# FAULTMUX register map
Vendor: Texas Instruments
Registers are 32-bit, access per field, no defined reset value unless marked. A register's access mark holds for its fields unless they carry their own. Offsets are as the file gives them; [hi:lo] are bit positions; {n}, {i} and the like mark numbered series; 'fields as' and 'values as' point back to an identical list.

## FAULTMUX (part 2 of 2) — top level module
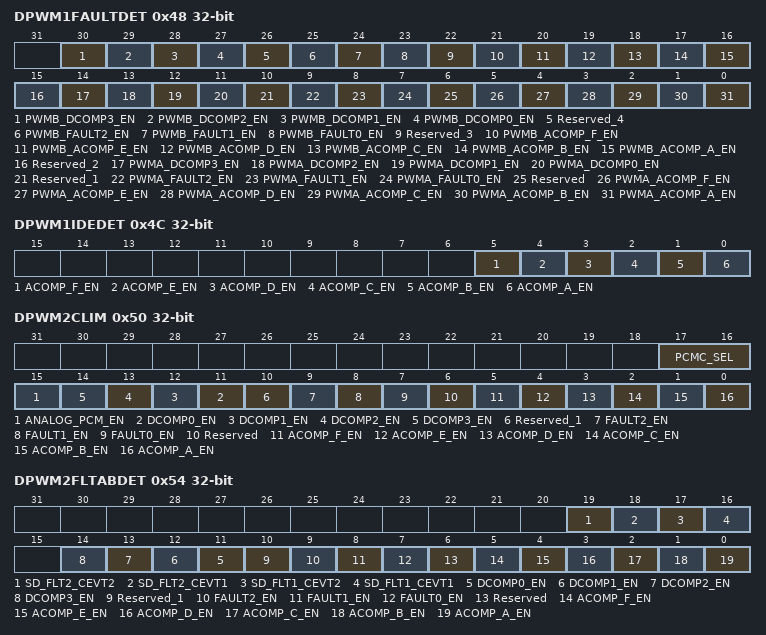
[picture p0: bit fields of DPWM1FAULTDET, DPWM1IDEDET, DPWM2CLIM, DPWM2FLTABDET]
0x48 DPWM1FAULTDET — DPWM 1 Fault Detection Register
  [30] PWMB_DCOMP3_EN rw — Enables Digital Comparator 3 result for DPWM_1 PWM-B Fault Detection
    1=enable (Digital Comparator 3 enabled for fault detection); 0=disbaled (Digital Comparator 3 disabled for fault detection (Default))
  [29] PWMB_DCOMP2_EN rw — Enables Digital Comparator 2 result for DPWM_1 PWM-B Fault Detection
    1=enable (Digital Comparator 2 enabled for fault detection); 0=disbaled (Digital Comparator 2 disabled for fault detection (Default))
  [28] PWMB_DCOMP1_EN rw — Enables Digital Comparator 1 result for DPWM_1 PWM-B Fault Detection
    1=enable (Digital Comparator 1 enabled for fault detection); 0=disbaled (Digital Comparator 1 disabled for fault detection (Default))
  [27] PWMB_DCOMP0_EN rw — Enables Digital Comparator 3 result for DPWM_1 PWM-B Fault Detection
    values as PWMB_DCOMP3_EN
  [26] Reserved_4 ro — Enables FAULT[3] pin for DPWM_1 PWM-B Fault Detection
    1=enable (External Fault pin enabled for fault detection); 0=disbaled (External Fault pin disabled for fault detection (Default))
  [25] PWMB_FAULT2_EN rw — Enables FAULT[2] pin for DPWM_1 PWM-B Fault Detection
    values as Reserved_4
  [24] PWMB_FAULT1_EN rw — Enables FAULT[1] pin for DPWM_1 PWM-B Fault Detection
    values as Reserved_4
  [23] PWMB_FAULT0_EN rw — Enables FAULT[0] pin for DPWM_1 PWM-B Fault Detection
    values as Reserved_4
  [22] Reserved_3 ro — Enables Analog Comparator G result for DPWM_1 PWM-B Fault detection
    1=enable (Analog Comparator result enabled for fault detection); 0=disbaled (Analog Comparator result disabled for fault detection (Default))
  [21] PWMB_ACOMP_F_EN rw — Enables Analog Comparator F result for DPWM_1 PWM-B Fault detection
    values as Reserved_3
  [20] PWMB_ACOMP_E_EN rw — Enables Analog Comparator E result for DPWM_1 PWM-B Fault detection
    values as Reserved_3
  [19] PWMB_ACOMP_D_EN rw — Enables Analog Comparator D result for DPWM_1 PWM-B Fault detection
    values as Reserved_3
  [18] PWMB_ACOMP_C_EN rw — Enables Analog Comparator C result for DPWM_1 PWM-B Fault detection
    values as Reserved_3
  [17] PWMB_ACOMP_B_EN rw — Enables Analog Comparator B result for DPWM_1 PWM-B Fault detection
    values as Reserved_3
  [16] PWMB_ACOMP_A_EN rw — Enables Analog Comparator A result for DPWM_1 PWM-B Fault detection
    values as Reserved_3
  [15] Reserved_2 ro — RESEVED
  [14] PWMA_DCOMP3_EN rw — Enables Digital Comparator 3 result for DPWM_1 PWM-A Fault Detection
    values as PWMB_DCOMP3_EN
  [13] PWMA_DCOMP2_EN rw — Enables Digital Comparator 2 result for DPWM_1 PWM-A Fault Detection
    values as PWMB_DCOMP2_EN
  [12] PWMA_DCOMP1_EN rw — Enables Digital Comparator 1 result for DPWM_1 PWM-A Fault Detection
    values as PWMB_DCOMP1_EN
  [11] PWMA_DCOMP0_EN rw — Enables Digital Comparator 3 result for DPWM_1 PWM-A Fault Detection
    values as PWMB_DCOMP3_EN
  [10] Reserved_1 ro — Enables FAULT[3] pin for DPWM_1 PWM-A Fault Detection
    values as Reserved_4
  [9] PWMA_FAULT2_EN rw — Enables FAULT[2] pin for DPWM_1 PWM-A Fault Detection
    values as Reserved_4
  [8] PWMA_FAULT1_EN rw — Enables FAULT[1] pin for DPWM_1 PWM-A Fault Detection
    values as Reserved_4
  [7] PWMA_FAULT0_EN rw — Enables FAULT[0] pin for DPWM_1 PWM-A Fault Detection
    values as Reserved_4
  [6] Reserved ro — Enables Analog Comparator G result for DPWM_1 PWM-A Fault detection
    values as Reserved_3
  [5] PWMA_ACOMP_F_EN rw — Enables Analog Comparator F result for DPWM_1 PWM-A Fault detection
    values as Reserved_3
  [4] PWMA_ACOMP_E_EN rw — Enables Analog Comparator E result for DPWM_1 PWM-A Fault detection
    values as Reserved_3
  [3] PWMA_ACOMP_D_EN rw — Enables Analog Comparator D result for DPWM_1 PWM-A Fault detection
    values as Reserved_3
  [2] PWMA_ACOMP_C_EN rw — Enables Analog Comparator C result for DPWM_1 PWM-A Fault detection
    values as Reserved_3
  [1] PWMA_ACOMP_B_EN rw — Enables Analog Comparator B result for DPWM_1 PWM-A Fault detection
    values as Reserved_3
  [0] PWMA_ACOMP_A_EN rw — Enables Analog Comparator A result for DPWM_1 PWM-A Fault detection
    values as Reserved_3
0x4C DPWM1IDEDET rw — DPWM 1 IDE detection register
  [all] fields
    1=enable; 0=disable
  [5] ACOMP_F_EN — Enables Analog Comparator F result for DPWM1 IDE detection
  [4] ACOMP_E_EN — Enables Analog Comparator E result for DPWM1 IDE detection
  [3] ACOMP_D_EN — Enables Analog Comparator D result for DPWM1 IDE detection
  [2] ACOMP_C_EN — Enables Analog Comparator C result for DPWM1 IDE detection
  [1] ACOMP_B_EN — Enables Analog Comparator B result for DPWM1 IDE detection
  [0] ACOMP_A_EN — Enables Analog Comparator A result for DPWM1 IDE detection
0x50 DPWM2CLIM access not given — DPWM_2 Current Limit Control Register
  [17:16] PCMC_SEL — Selects the PCMC module to trigger PCMC- CBC fault
    2=PCMC3; 1=PCMC2; 0=PCMC1
  [15] ANALOG_PCM_EN rw — Enables Analog Peak Current detection result for DPWM_2 Current Limit
    1=enabled (Analog Peak Current detection enabled for current limit); 0=disabled (Analog Peak Current detection disabled for current limit (Default))
  [n+11] DCOMP{n}_EN rw (n=0..3) — Enables Digital Comparator {n} result for DPWM_2 Current Limit
    values as ANALOG_PCM_EN
  [10] Reserved_1 ro — Enables FAULT[3] pin for DPWM_2 Current Limit
    1=enabled (External Fault pin enabled for current limit); 0=disabled (External Fault pin disabled for current limit (Default))
  [9] FAULT2_EN rw — Enables FAULT[2] pin for DPWM_2 Current Limit
    values as Reserved_1
  [8] FAULT1_EN rw — Enables FAULT[1] pin for DPWM_2 Current Limit
    values as Reserved_1
  [7] FAULT0_EN rw — Enables FAULT[0] pin for DPWM_2 Current Limit
    values as Reserved_1
  [6] Reserved ro — Enables Analog Comparator G result for DPWM_2 Current Limit
    1=enabled (Analog Comparator result enabled for current limit); 0=disabled (Analog Comparator result disabled for current limit (Default))
  [5] ACOMP_F_EN rw — Enables Analog Comparator F result for DPWM_2 Current Limit
    values as Reserved
  [4] ACOMP_E_EN rw — Enables Analog Comparator E result for DPWM_2 Current Limit
    values as Reserved
  [3] ACOMP_D_EN rw — Enables Analog Comparator D result for DPWM_2 Current Limit
    values as Reserved
  [2] ACOMP_C_EN rw — Enables Analog Comparator C result for DPWM_2 Current Limit
    values as Reserved
  [1] ACOMP_B_EN rw — Enables Analog Comparator B result for DPWM_2 Current Limit
    values as Reserved
  [0] ACOMP_A_EN rw — Enables Analog Comparator A result for DPWM_2 Current Limit
    values as Reserved
0x54 DPWM2FLTABDET — DPWM_2 Fault AB Detection Register
  [19] SD_FLT2_CEVT2 rw — Enables SDFM Filter2 Compare Event 2 output for DPWM2 Fault detection
  [18] SD_FLT2_CEVT1 rw — Enables SDFM Filter2 Compare Event 1 output for DPWM2 Fault detection
  [17] SD_FLT1_CEVT2 rw — Enables SDFM Filter1 Compare Event 2 output for DPWM2 Fault detection
  [16] SD_FLT1_CEVT1 rw — Enables SDFM Filter1 Compare Event 1 output for DPWM2 Fault detection
  [n+11] DCOMP{n}_EN rw (n=0..3) — Enables Digital Comparator {n} result for DPWM_2 Fault AB Detection
    1=enable (Digital Comparator {n} result enabled for current limit); 0=disable (Digital Comparator {n} result disabled for current limit (Default))
  [10] Reserved_1 ro — Enables FAULT[3] pin for DPWM_2 Current Limit
    1=enable (External Fault pin enabled for current limit); 0=disable (External Fault pin disabled for current limit (Default))
  [9] FAULT2_EN rw — Enables FAULT[2] pin for DPWM_2 Fault AB Detection
    values as Reserved_1
  [8] FAULT1_EN rw — Enables FAULT[1] pin for DPWM_2 Fault AB Detection
    values as Reserved_1
  [7] FAULT0_EN rw — Enables FAULT[0] pin for DPWM_2 Fault AB Detection
    values as Reserved_1
  [6] Reserved ro — Enables Analog Comparator G result for DPWM_2 Current Limit
    1=enable (Analog Comparator result enabled for current limit); 0=disable (Analog Comparator result disabled for current limit (Default))
  [5] ACOMP_F_EN rw — Enables Analog Comparator F result for DPWM_2 Fault AB Detection
    values as Reserved
  [4] ACOMP_E_EN rw — Enables Analog Comparator E result for DPWM_2 Fault AB Detection
    values as Reserved
  [3] ACOMP_D_EN rw — Enables Analog Comparator D result for DPWM_2 Fault AB Detection
    values as Reserved
  [2] ACOMP_C_EN rw — Enables Analog Comparator C result for DPWM_2 Fault AB Detection
    values as Reserved
  [1] ACOMP_B_EN rw — Enables Analog Comparator B result for DPWM_2 Fault AB Detection
    values as Reserved
  [0] ACOMP_A_EN rw — Enables Analog Comparator A result for DPWM_2 Fault AB Detection
    values as Reserved
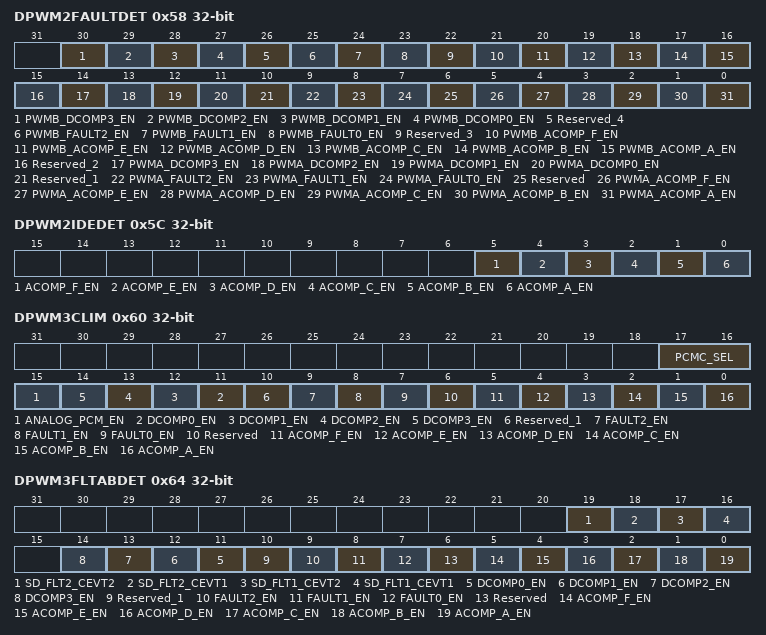
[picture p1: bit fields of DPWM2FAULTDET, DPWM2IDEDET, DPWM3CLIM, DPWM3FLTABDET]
0x58 DPWM2FAULTDET — DPWM_2 Fault Detection Register
  [30] PWMB_DCOMP3_EN rw — Enables Digital Comparator 3 result for DPWM_2 PWM-B Fault Detection
    values as DPWM1FAULTDET.PWMB_DCOMP3_EN
  [29] PWMB_DCOMP2_EN rw — Enables Digital Comparator 2 result for DPWM_2 PWM-B Fault Detection
    values as DPWM1FAULTDET.PWMB_DCOMP2_EN
  [28] PWMB_DCOMP1_EN rw — Enables Digital Comparator 1 result for DPWM_2 PWM-B Fault Detection
    values as DPWM1FAULTDET.PWMB_DCOMP1_EN
  [27] PWMB_DCOMP0_EN rw — Enables Digital Comparator 3 result for DPWM_2 PWM-B Fault Detection
    values as DPWM1FAULTDET.PWMB_DCOMP3_EN
  [26] Reserved_4 ro — Enables FAULT[3] pin for DPWM_2 PWM-B Fault Detection
    values as DPWM1FAULTDET.Reserved_4
  [25] PWMB_FAULT2_EN rw — Enables FAULT[2] pin for DPWM_2 PWM-B Fault Detection
    values as DPWM1FAULTDET.Reserved_4
  [24] PWMB_FAULT1_EN rw — Enables FAULT[1] pin for DPWM_2 PWM-B Fault Detection
    values as DPWM1FAULTDET.Reserved_4
  [23] PWMB_FAULT0_EN rw — Enables FAULT[0] pin for DPWM_2 PWM-B Fault Detection
    values as DPWM1FAULTDET.Reserved_4
  [22] Reserved_3 ro — Enables Analog Comparator G result for DPWM_2 PWM-B Fault detection
    values as DPWM1FAULTDET.Reserved_3
  [21] PWMB_ACOMP_F_EN rw — Enables Analog Comparator F result for DPWM_2 PWM-B Fault detection
    values as DPWM1FAULTDET.Reserved_3
  [20] PWMB_ACOMP_E_EN rw — Enables Analog Comparator E result for DPWM_2 PWM-B Fault detection
    values as DPWM1FAULTDET.Reserved_3
  [19] PWMB_ACOMP_D_EN rw — Enables Analog Comparator D result for DPWM_2 PWM-B Fault detection
    values as DPWM1FAULTDET.Reserved_3
  [18] PWMB_ACOMP_C_EN rw — Enables Analog Comparator C result for DPWM_2 PWM-B Fault detection
    values as DPWM1FAULTDET.Reserved_3
  [17] PWMB_ACOMP_B_EN rw — Enables Analog Comparator B result for DPWM_2 PWM-B Fault detection
    values as DPWM1FAULTDET.Reserved_3
  [16] PWMB_ACOMP_A_EN rw — Enables Analog Comparator A result for DPWM_2 PWM-B Fault detection
    values as DPWM1FAULTDET.Reserved_3
  [15] Reserved_2 ro — RESEVED
  [14] PWMA_DCOMP3_EN rw — Enables Digital Comparator 3 result for DPWM_2 PWM-A Fault Detection
    values as DPWM1FAULTDET.PWMB_DCOMP3_EN
  [13] PWMA_DCOMP2_EN rw — Enables Digital Comparator 2 result for DPWM_2 PWM-A Fault Detection
    values as DPWM1FAULTDET.PWMB_DCOMP2_EN
  [12] PWMA_DCOMP1_EN rw — Enables Digital Comparator 1 result for DPWM_2 PWM-A Fault Detection
    values as DPWM1FAULTDET.PWMB_DCOMP1_EN
  [11] PWMA_DCOMP0_EN rw — Enables Digital Comparator 3 result for DPWM_2 PWM-A Fault Detection
    values as DPWM1FAULTDET.PWMB_DCOMP3_EN
  [10] Reserved_1 ro — Enables FAULT[3] pin for DPWM_2 PWM-A Fault Detection
    values as DPWM1FAULTDET.Reserved_4
  [9] PWMA_FAULT2_EN rw — Enables FAULT[2] pin for DPWM_2 PWM-A Fault Detection
    values as DPWM1FAULTDET.Reserved_4
  [8] PWMA_FAULT1_EN rw — Enables FAULT[1] pin for DPWM_2 PWM-A Fault Detection
    values as DPWM1FAULTDET.Reserved_4
  [7] PWMA_FAULT0_EN rw — Enables FAULT[0] pin for DPWM_2 PWM-A Fault Detection
    values as DPWM1FAULTDET.Reserved_4
  [6] Reserved ro — Enables Analog Comparator G result for DPWM_2 PWM-A Fault detection
    values as DPWM1FAULTDET.Reserved_3
  [5] PWMA_ACOMP_F_EN rw — Enables Analog Comparator F result for DPWM_2 PWM-A Fault detection
    values as DPWM1FAULTDET.Reserved_3
  [4] PWMA_ACOMP_E_EN rw — Enables Analog Comparator E result for DPWM_2 PWM-A Fault detection
    values as DPWM1FAULTDET.Reserved_3
  [3] PWMA_ACOMP_D_EN rw — Enables Analog Comparator D result for DPWM_2 PWM-A Fault detection
    values as DPWM1FAULTDET.Reserved_3
  [2] PWMA_ACOMP_C_EN rw — Enables Analog Comparator C result for DPWM_2 PWM-A Fault detection
    values as DPWM1FAULTDET.Reserved_3
  [1] PWMA_ACOMP_B_EN rw — Enables Analog Comparator B result for DPWM_2 PWM-A Fault detection
    values as DPWM1FAULTDET.Reserved_3
  [0] PWMA_ACOMP_A_EN rw — Enables Analog Comparator A result for DPWM_2 PWM-A Fault detection
    values as DPWM1FAULTDET.Reserved_3
0x5C DPWM2IDEDET rw — DPWM 2 IDE detection register
  [all] fields
    1=enable; 0=disable
  [5] ACOMP_F_EN — Enables Analog Comparator F result for DPWM2 IDE detection
  [4] ACOMP_E_EN — Enables Analog Comparator E result for DPWM2 IDE detection
  [3] ACOMP_D_EN — Enables Analog Comparator D result for DPWM2 IDE detection
  [2] ACOMP_C_EN — Enables Analog Comparator C result for DPWM2 IDE detection
  [1] ACOMP_B_EN — Enables Analog Comparator B result for DPWM2 IDE detection
  [0] ACOMP_A_EN — Enables Analog Comparator A result for DPWM2 IDE detection
0x60 DPWM3CLIM access not given — DPWM_3 Current Limit Control Register
  [17:16] PCMC_SEL — Selects the PCMC module to trigger PCMC- CBC fault
    2=PCMC3; 1=PCMC2; 0=PCMC1
  [15] ANALOG_PCM_EN rw — Enables Analog Peak Current detection result for DPWM_3 Current Limit
    values as DPWM2CLIM.ANALOG_PCM_EN
  [n+11] DCOMP{n}_EN rw (n=0..3) — Enables Digital Comparator {n} result for DPWM_3 Current Limit
    values as DPWM2CLIM.ANALOG_PCM_EN
  [10] Reserved_1 ro — Enables FAULT[3] pin for DPWM_3 Current Limit
    values as DPWM2CLIM.Reserved_1
  [9] FAULT2_EN rw — Enables FAULT[2] pin for DPWM_3 Current Limit
    values as DPWM2CLIM.Reserved_1
  [8] FAULT1_EN rw — Enables FAULT[1] pin for DPWM_3 Current Limit
    values as DPWM2CLIM.Reserved_1
  [7] FAULT0_EN rw — Enables FAULT[0] pin for DPWM_3 Current Limit
    values as DPWM2CLIM.Reserved_1
  [6] Reserved ro — Enables Analog Comparator G result for DPWM_3 Current Limit
    values as DPWM2CLIM.Reserved
  [5] ACOMP_F_EN rw — Enables Analog Comparator F result for DPWM_3 Current Limit
    values as DPWM2CLIM.Reserved
  [4] ACOMP_E_EN rw — Enables Analog Comparator E result for DPWM_3 Current Limit
    values as DPWM2CLIM.Reserved
  [3] ACOMP_D_EN rw — Enables Analog Comparator D result for DPWM_3 Current Limit
    values as DPWM2CLIM.Reserved
  [2] ACOMP_C_EN rw — Enables Analog Comparator C result for DPWM_3 Current Limit
    values as DPWM2CLIM.Reserved
  [1] ACOMP_B_EN rw — Enables Analog Comparator B result for DPWM_3 Current Limit
    values as DPWM2CLIM.Reserved
  [0] ACOMP_A_EN rw — Enables Analog Comparator A result for DPWM_3 Current Limit
    values as DPWM2CLIM.Reserved
0x64 DPWM3FLTABDET — DPWM_3 Fault AB Detection Register
  [19] SD_FLT2_CEVT2 rw — Enables SDFM Filter2 Compare Event 2 output for DPWM3 Fault detection
  [18] SD_FLT2_CEVT1 rw — Enables SDFM Filter2 Compare Event 1 output for DPWM3 Fault detection
  [17] SD_FLT1_CEVT2 rw — Enables SDFM Filter1 Compare Event 2 output for DPWM3 Fault detection
  [16] SD_FLT1_CEVT1 rw — Enables SDFM Filter1 Compare Event 1 output for DPWM3 Fault detection
  [n+11] DCOMP{n}_EN rw (n=0..3) — Enables Digital Comparator {n} result for DPWM_3 Fault AB Detection
    values as DPWM2FLTABDET.DCOMP0_EN
  [10] Reserved_1 ro — Enables FAULT[3] pin for DPWM_3 Current Limit
    values as DPWM2FLTABDET.Reserved_1
  [9] FAULT2_EN rw — Enables FAULT[2] pin for DPWM_3 Fault AB Detection
    values as DPWM2FLTABDET.Reserved_1
  [8] FAULT1_EN rw — Enables FAULT[1] pin for DPWM_3 Fault AB Detection
    values as DPWM2FLTABDET.Reserved_1
  [7] FAULT0_EN rw — Enables FAULT[0] pin for DPWM_3 Fault AB Detection
    values as DPWM2FLTABDET.Reserved_1
  [6] Reserved ro — Enables Analog Comparator G result for DPWM_3 Current Limit
    values as DPWM2FLTABDET.Reserved
  [5] ACOMP_F_EN rw — Enables Analog Comparator F result for DPWM_3 Fault AB Detection
    values as DPWM2FLTABDET.Reserved
  [4] ACOMP_E_EN rw — Enables Analog Comparator E result for DPWM_3 Fault AB Detection
    values as DPWM2FLTABDET.Reserved
  [3] ACOMP_D_EN rw — Enables Analog Comparator D result for DPWM_3 Fault AB Detection
    values as DPWM2FLTABDET.Reserved
  [2] ACOMP_C_EN rw — Enables Analog Comparator C result for DPWM_3 Fault AB Detection
    values as DPWM2FLTABDET.Reserved
  [1] ACOMP_B_EN rw — Enables Analog Comparator B result for DPWM_3 Fault AB Detection
    values as DPWM2FLTABDET.Reserved
  [0] ACOMP_A_EN rw — Enables Analog Comparator A result for DPWM_3 Fault AB Detection
    values as DPWM2FLTABDET.Reserved
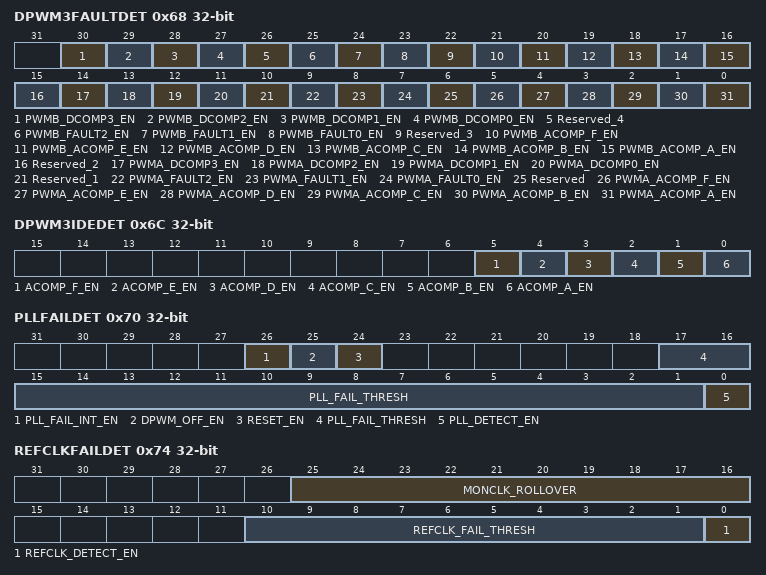
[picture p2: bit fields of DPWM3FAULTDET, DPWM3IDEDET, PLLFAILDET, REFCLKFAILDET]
0x68 DPWM3FAULTDET — DPWM 1 Fault Detection Register
  [30] PWMB_DCOMP3_EN rw — Enables Digital Comparator 3 result for DPWM_3 PWM-B Fault Detection
    values as DPWM1FAULTDET.PWMB_DCOMP3_EN
  [29] PWMB_DCOMP2_EN rw — Enables Digital Comparator 2 result for DPWM_3 PWM-B Fault Detection
    values as DPWM1FAULTDET.PWMB_DCOMP2_EN
  [28] PWMB_DCOMP1_EN rw — Enables Digital Comparator 1 result for DPWM_3 PWM-B Fault Detection
    values as DPWM1FAULTDET.PWMB_DCOMP1_EN
  [27] PWMB_DCOMP0_EN rw — Enables Digital Comparator 3 result for DPWM_3 PWM-B Fault Detection
    values as DPWM1FAULTDET.PWMB_DCOMP3_EN
  [26] Reserved_4 ro — Enables FAULT[3] pin for DPWM_3 PWM-B Fault Detection
    values as DPWM1FAULTDET.Reserved_4
  [25] PWMB_FAULT2_EN rw — Enables FAULT[2] pin for DPWM_3 PWM-B Fault Detection
    values as DPWM1FAULTDET.Reserved_4
  [24] PWMB_FAULT1_EN rw — Enables FAULT[1] pin for DPWM_3 PWM-B Fault Detection
    values as DPWM1FAULTDET.Reserved_4
  [23] PWMB_FAULT0_EN rw — Enables FAULT[0] pin for DPWM_3 PWM-B Fault Detection
    values as DPWM1FAULTDET.Reserved_4
  [22] Reserved_3 ro — Enables Analog Comparator G result for DPWM_3 PWM-B Fault detection
    values as DPWM1FAULTDET.Reserved_3
  [21] PWMB_ACOMP_F_EN rw — Enables Analog Comparator F result for DPWM_3 PWM-B Fault detection
    values as DPWM1FAULTDET.Reserved_3
  [20] PWMB_ACOMP_E_EN rw — Enables Analog Comparator E result for DPWM_3 PWM-B Fault detection
    values as DPWM1FAULTDET.Reserved_3
  [19] PWMB_ACOMP_D_EN rw — Enables Analog Comparator D result for DPWM_3 PWM-B Fault detection
    values as DPWM1FAULTDET.Reserved_3
  [18] PWMB_ACOMP_C_EN rw — Enables Analog Comparator C result for DPWM_3 PWM-B Fault detection
    values as DPWM1FAULTDET.Reserved_3
  [17] PWMB_ACOMP_B_EN rw — Enables Analog Comparator B result for DPWM_3 PWM-B Fault detection
    values as DPWM1FAULTDET.Reserved_3
  [16] PWMB_ACOMP_A_EN rw — Enables Analog Comparator A result for DPWM_3 PWM-B Fault detection
    values as DPWM1FAULTDET.Reserved_3
  [15] Reserved_2 ro — RESEVED
  [14] PWMA_DCOMP3_EN rw — Enables Digital Comparator 3 result for DPWM_3 PWM-A Fault Detection
    values as DPWM1FAULTDET.PWMB_DCOMP3_EN
  [13] PWMA_DCOMP2_EN rw — Enables Digital Comparator 2 result for DPWM_3 PWM-A Fault Detection
    values as DPWM1FAULTDET.PWMB_DCOMP2_EN
  [12] PWMA_DCOMP1_EN rw — Enables Digital Comparator 1 result for DPWM_3 PWM-A Fault Detection
    values as DPWM1FAULTDET.PWMB_DCOMP1_EN
  [11] PWMA_DCOMP0_EN rw — Enables Digital Comparator 3 result for DPWM_3 PWM-A Fault Detection
    values as DPWM1FAULTDET.PWMB_DCOMP3_EN
  [10] Reserved_1 ro — Enables FAULT[3] pin for DPWM_3 PWM-A Fault Detection
    values as DPWM1FAULTDET.Reserved_4
  [9] PWMA_FAULT2_EN rw — Enables FAULT[2] pin for DPWM_3 PWM-A Fault Detection
    values as DPWM1FAULTDET.Reserved_4
  [8] PWMA_FAULT1_EN rw — Enables FAULT[1] pin for DPWM_3 PWM-A Fault Detection
    values as DPWM1FAULTDET.Reserved_4
  [7] PWMA_FAULT0_EN rw — Enables FAULT[0] pin for DPWM_3 PWM-A Fault Detection
    values as DPWM1FAULTDET.Reserved_4
  [6] Reserved ro — Enables Analog Comparator G result for DPWM_3 PWM-A Fault detection
    values as DPWM1FAULTDET.Reserved_3
  [5] PWMA_ACOMP_F_EN rw — Enables Analog Comparator F result for DPWM_3 PWM-A Fault detection
    values as DPWM1FAULTDET.Reserved_3
  [4] PWMA_ACOMP_E_EN rw — Enables Analog Comparator E result for DPWM_3 PWM-A Fault detection
    values as DPWM1FAULTDET.Reserved_3
  [3] PWMA_ACOMP_D_EN rw — Enables Analog Comparator D result for DPWM_3 PWM-A Fault detection
    values as DPWM1FAULTDET.Reserved_3
  [2] PWMA_ACOMP_C_EN rw — Enables Analog Comparator C result for DPWM_3 PWM-A Fault detection
    values as DPWM1FAULTDET.Reserved_3
  [1] PWMA_ACOMP_B_EN rw — Enables Analog Comparator B result for DPWM_3 PWM-A Fault detection
    values as DPWM1FAULTDET.Reserved_3
  [0] PWMA_ACOMP_A_EN rw — Enables Analog Comparator A result for DPWM_3 PWM-A Fault detection
    values as DPWM1FAULTDET.Reserved_3
0x6C DPWM3IDEDET rw — DPWM 3 IDE detection register
  [all] fields
    1=enable; 0=disable
  [5] ACOMP_F_EN — Enables Analog Comparator F result for DPWM3 IDE detection
  [4] ACOMP_E_EN
  [3] ACOMP_D_EN — Enables Analog Comparator D result for DPWM3 IDE detection
  [2] ACOMP_C_EN — Enables Analog Comparator C result for DPWM3 IDE detection
  [1] ACOMP_B_EN — Enables Analog Comparator B result for DPWM3 IDE detection
  [0] ACOMP_A_EN — Enables Analog Comparator A result for DPWM3 IDE detection
0x70 PLLFAILDET — PLL Fail Detect Register
  [26] PLL_FAIL_INT_EN rw — Enables interrupt (mapped to FAULT_INT)on overflow of the MONITOR_CLK counter indicating PLL failure.
    1=Enable interrupt on PLL failure; 0=Disable interrupt on PLL failure
  [25] DPWM_OFF_EN rw — Enables turn OFF of all DPWM modules in the event of PLL failure detection
    1=enable (Turn off all DPWM modules on PLL failure detection); 0=disable (Do not turn off DPWM modules on PLL failure detection)
  [24] RESET_EN rw — Enables chip reset on PLL failure.
    1=enable (Chip reset on PLL failure); 0=disable (No chip reset on PLL failure)
  [17:1] PLL_FAIL_THRESH rw — Configures threshold where a clear flag is used to clear a counter in the Low Frequency Oscillator domain (if LFO counter overflows, a reset will be generated), resolution of threshold equals High Frequency Oscillator period
  [0] PLL_DETECT_EN rw — Enables High Frequency Oscillator Failure Detection logic
    1=Enables High Frequency Oscillator Failure Detection; 0=Disables High Frequency Oscillator Failure Detection (Default)
0x74 REFCLKFAILDET — REFCLK Fail Detect Register
  [25:16] MONCLK_ROLLOVER rw — Configures threshold where a clear flag is used to clear a counter running from REF_CLK
    1=enable; 0=disable
  [10:1] REFCLK_FAIL_THRESH rw — Configures threshold where a clear flag is used to clear a counter in the High Frequency Oscillator domain (if HFO counter overflows, a reset will be generated), resolution of threshold equals Low Frequency Oscillator period
  [0] REFCLK_DETECT_EN rw — Enables REF_CLK Failure Detection logic, interrupt will be generated upon detection of an oscillator failure
    1=Enables REFCLK Failure Detection; 0=Disables REFCLK Failure Detection (Default)
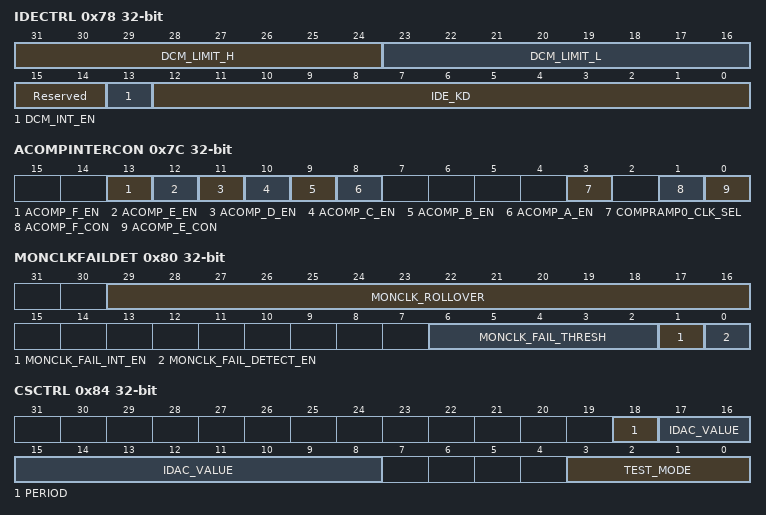
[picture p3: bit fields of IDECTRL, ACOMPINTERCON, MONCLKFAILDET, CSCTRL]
0x78 IDECTRL — IDE Control Register
  [31:24] DCM_LIMIT_H rw — Value added to 1-Da value to provide hysteresis for exiting DCM mode
  [23:16] DCM_LIMIT_L rw — Value subtracted from 1-Da value to provide hysteresis for entering DCM mode
  [15:14] Reserved ro — resrved
  [13] DCM_INT_EN rw — Enables Discontinuous Conduction Mode (DCM) interrupt generation based on selected Filter outputs
    1=Enables DCM Detection Interrupt; 0=Disables DCM Detection Interrupt (Default)
  [12:0] IDE_KD rw — 13-bit unsigned value used to calculate the DPWM B Pulse width when configured in IDE Mode. IDE_KD is configured in 4.9 format, with the integer portion of the KD value ranging from 0 to 15 and 9 fractional bits available for the pulse width calculation
0x7C ACOMPINTERCON — ACOMP interconnection register
  [13] ACOMP_F_EN rw — Enable analog comparator and DAC F
  [12] ACOMP_E_EN rw — Enable analog comparator and DAC E
  [11] ACOMP_D_EN rw — Enable analog comparator and DAC D
  [10] ACOMP_C_EN rw — Enable analog comparator and DAC C
  [9] ACOMP_B_EN rw — Enable analog comparator and DAC B
  [8] ACOMP_A_EN rw — Enable analog comparator and DAC A
  [3] COMPRAMP0_CLK_SEL rw — Selects the clock for slope compensation ramp for COMPRAMP0.
    1=ICLK; 0=ICLK_divided_by_2
  [1] ACOMP_F_CON rw — Connects ACOMP_F Comparator input to ACOMP_D input (AD04)
    1=AD04 (ACOMP_F Comparator input connected to AD04); 0=AD06 (ACOMP_F comparator input connected to AD06)
  [0] ACOMP_E_CON rw — Connects ACOMP_E Comparator input to ACOMP_A input (AD02)
    1=AD02 (ACOMP_E Comparator input connected to AD02); 0=AD05 (ACOMP_E comparator input connected to AD05)
0x80 MONCLKFAILDET
  [29:16] MONCLK_ROLLOVER rw
  [6:2] MONCLK_FAIL_THRESH rw
  [1] MONCLK_FAIL_INT_EN rw
    1=enable; 0=disable
  [0] MONCLK_FAIL_DETECT_EN rw
    1=enable; 0=disable
0x84 CSCTRL rw — Current share control register
  [18] PERIOD — Dither period for IDAC 4 bits
  [17:8] IDAC_VALUE — IDAC 10 bit value with a resolution of 78.125nA per lsb
  [3:0] TEST_MODE — Controls current sharing operation
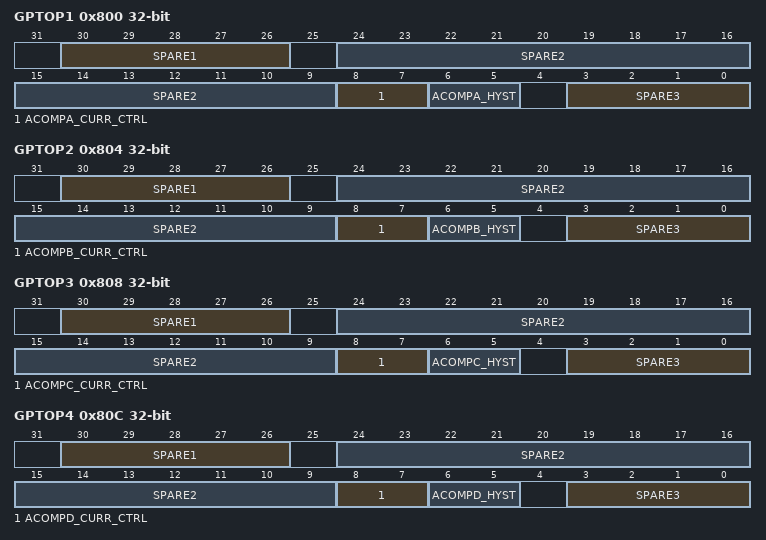
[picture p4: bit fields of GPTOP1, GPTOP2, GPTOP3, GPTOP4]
0x800 GPTOP1
  [30:26] SPARE1 rw — Spare
  [24:9] SPARE2 rw
  [8:7] ACOMPA_CURR_CTRL rw — Controls the speed of ACOMPA
  [6:5] ACOMPA_HYST rw — Programmability for hysterisis of ACOMPA
  [3:0] SPARE3 rw
0x804 GPTOP2
  [30:26] SPARE1 rw — Spare
  [24:9] SPARE2 rw
  [8:7] ACOMPB_CURR_CTRL rw — Controls the speed of ACOMPB
  [6:5] ACOMPB_HYST rw — Programmability for hysterisis of ACOMPB
  [3:0] SPARE3 rw
0x808 GPTOP3
  [30:26] SPARE1 rw — Spare
  [24:9] SPARE2 rw
  [8:7] ACOMPC_CURR_CTRL rw — Controls the speed of ACOMPC
  [6:5] ACOMPC_HYST rw — Programmability for hysterisis of ACOMPC
  [3:0] SPARE3 rw
0x80C GPTOP4
  [30:26] SPARE1 rw — Spare
  [24:9] SPARE2 rw
  [8:7] ACOMPD_CURR_CTRL rw — Controls the speed of ACOMPD
  [6:5] ACOMPD_HYST rw — Programmability for hysterisis of ACOMPD
  [3:0] SPARE3 rw
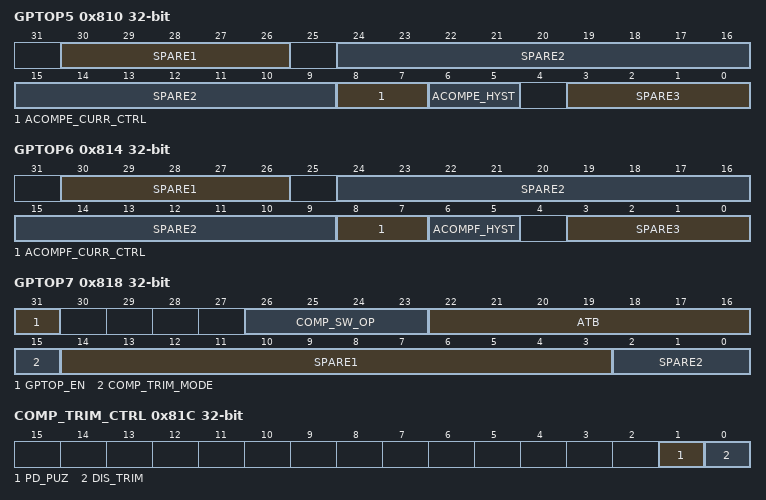
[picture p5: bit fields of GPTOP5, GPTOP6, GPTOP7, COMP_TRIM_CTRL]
0x810 GPTOP5
  [30:26] SPARE1 rw — Spare
  [24:9] SPARE2 rw
  [8:7] ACOMPE_CURR_CTRL rw — Controls the speed of ACOMPE
  [6:5] ACOMPE_HYST rw — Programmability for hysterisis of ACOMPE
  [3:0] SPARE3 rw
0x814 GPTOP6
  [30:26] SPARE1 rw — Spare
  [24:9] SPARE2 rw
  [8:7] ACOMPF_CURR_CTRL rw — Controls the speed of ACOMPF
  [6:5] ACOMPF_HYST rw — Programmability for hysterisis of ACOMPF
  [3:0] SPARE3 rw
0x818 GPTOP7
  [31] GPTOP_EN rw — Enable complete gptop
  [26:23] COMP_SW_OP rw — Comparator SW output
  [22:16] ATB rw — Test mode signal
  [15] COMP_TRIM_MODE rw — Enables auto calibration of comparators
  [14:3] SPARE1 rw — Spare
  [2:0] SPARE2 rw — Spare
0x81C COMP_TRIM_CTRL — Comparator Trim Control Register
  [1] PD_PUZ rw — Pullup/pulldown comparator input stage
  [0] DIS_TRIM rw — Disable Trim Mode
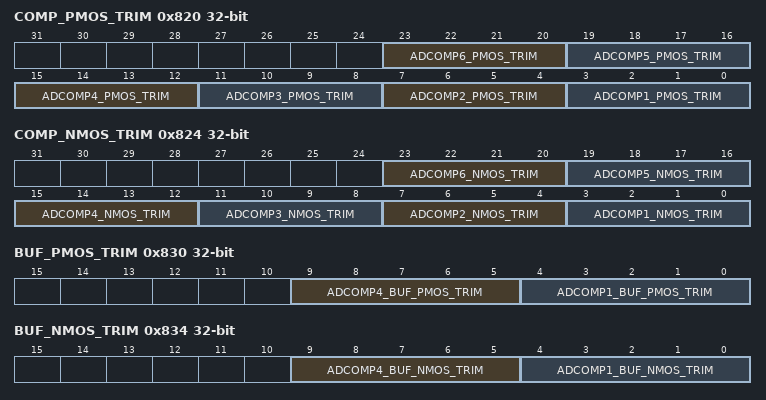
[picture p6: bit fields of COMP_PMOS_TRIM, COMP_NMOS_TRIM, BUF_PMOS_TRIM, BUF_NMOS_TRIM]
0x820 COMP_PMOS_TRIM — Comparator PMOS Trim Register
  [23:20] ADCOMP6_PMOS_TRIM rw — ACOMPF pmos trim code(ADCOMP6)
  [19:16] ADCOMP5_PMOS_TRIM rw — ACOMPE pmos trim code(ADCOMP5)
  [15:12] ADCOMP4_PMOS_TRIM rw — ACOMPD pmos trim code(ADCOMP4)
  [11:8] ADCOMP3_PMOS_TRIM rw — ACOMPC pmos trim code(ADCOMP3)
  [7:4] ADCOMP2_PMOS_TRIM rw — ACOMPB pmos trim code(ADCOMP2)
  [3:0] ADCOMP1_PMOS_TRIM rw — ACOMPA pmos trim code(ADCOMP1)
0x824 COMP_NMOS_TRIM — Comparator NMOS Trim Register
  [23:20] ADCOMP6_NMOS_TRIM rw — ACOMPF nmos trim code(ADCOMP6)
  [19:16] ADCOMP5_NMOS_TRIM rw — ACOMPE nmos trim code(ADCOMP5)
  [15:12] ADCOMP4_NMOS_TRIM rw — ACOMPD nmos trim code(ADCOMP4)
  [11:8] ADCOMP3_NMOS_TRIM rw — ACOMPC nmos trim code(ADCOMP3)
  [7:4] ADCOMP2_NMOS_TRIM rw — ACOMPB nmos trim code(ADCOMP2)
  [3:0] ADCOMP1_NMOS_TRIM rw — ACOMPA nmos trim code(ADCOMP1)
0x828 COMP_TRIM_OUT ro — Comparator Output Register
  [5:0] ACOMP_OUT — Comparator Outputs
0x82C BUF_TRIM_CTRL — Buffer Trim Control Register
  [3:0] DAC_BUFFER_MODE rw
0x830 BUF_PMOS_TRIM — Buffer PMOS Trim Register
  [9:5] ADCOMP4_BUF_PMOS_TRIM rw — ACOMPD pmos trim code(ADCOMP4)
  [4:0] ADCOMP1_BUF_PMOS_TRIM rw — ACOMPA pmos trim code(ADCOMP1)
0x834 BUF_NMOS_TRIM — Buffer NMOS Trim Register
  [9:5] ADCOMP4_BUF_NMOS_TRIM rw — ACOMPD nmos trim code(ADCOMP4)
  [4:0] ADCOMP1_BUF_NMOS_TRIM rw — ACOMPA nmos trim code(ADCOMP1)
0x838 BUF_TRIM_OUT ro — Buffer Output Register
  [5:0] BUF_OUT — Comparator Buffer Outputs
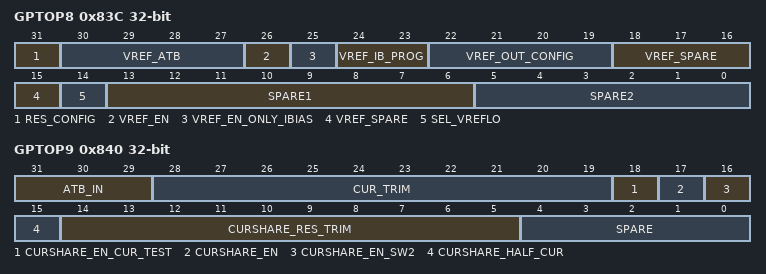
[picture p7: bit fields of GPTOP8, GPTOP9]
0x83C GPTOP8 rw
  [31] RES_CONFIG
  [30:27] VREF_ATB — ATB select bits for 2.5V reference buffer
  [26] VREF_EN — Enables the 2.5V reference buffer
  [25] VREF_EN_ONLY_IBIAS — Enables only ibias for 2.5V reference buffer
  [24:23] VREF_IB_PROG — Current programmability for 2.5V reference buffer
  [22:19] VREF_OUT_CONFIG — Trim bits
  [18:15] VREF_SPARE — Buffer spare
  [14] SEL_VREFLO
  [13:6] SPARE1 — 2.5V buffer trim bits
  [5:0] SPARE2 — Spare
0x840 GPTOP9 rw
  [31:29] ATB_IN — ATB select signal for current share
  [28:19] CUR_TRIM — Trim bits for current trim
  [18] CURSHARE_EN_CUR_TEST — Unused
  [17] CURSHARE_EN — Enables current share module
  [16] CURSHARE_EN_SW2 — Enables curshare output to be sensed by internal ADC
  [15] CURSHARE_HALF_CUR — Switches off half the current
  [14:5] CURSHARE_RES_TRIM — Trim bits for resistor trim
  [4:0] SPARE — Modes of opration
